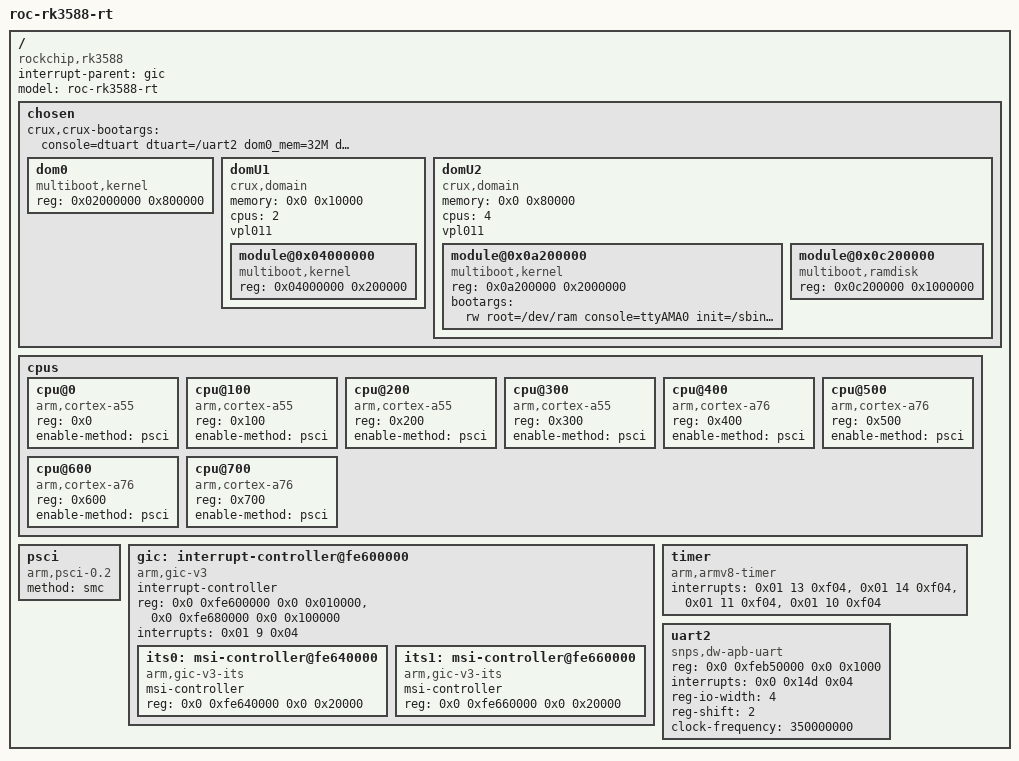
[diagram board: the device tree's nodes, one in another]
/******************************************************
 *                     _____     __  __
 *            /\/\/\/\/ __  \/\ / _\/__\
 *            \ - \ \ \ \/ // // _\/  \
 *             \/\/\_/\_/\/ \__\__\\/\/ @2025
 *
 *                  - Hustle Embedded -
 *****************************************************/

/dts-v1/;

/ {
	#address-cells = <2>;
	#size-cells = <2>;
	interrupt-parent = <&gic>;
	compatible = "rockchip,rk3588";
	model = "roc-rk3588-rt";

	/* ROC-RK3588-RT Android 12 u-boot: bdinfo
	 *
	 * arch_number = 0x00000000
	 * boot_params = 0x00000000
	 * DRAM bank   = 0x00000000
	 * -> start    = 0x00200000
	 * -> size     = 0x08200000
	 * DRAM bank   = 0x00000001
	 * -> start    = 0x09400000
	 * -> size     = 0xE6C00000
	 * baudrate    = 1500000 bps
	 * TLB addr    = 0xEFFF0000
	 * relocaddr   = 0xEDC35000
	 * reloc off   = 0xEDA35000
	 * irq_sp      = 0xEB9F9EA0
	 * sp start    = 0xEB9F9EA0
	 * Early malloc usage: 31f8 / 80000
	 * fdt_blob = 0000000008300000
	 */
	chosen {
		#address-cells = <1>;
		#size-cells = <1>;
		crux,crux-bootargs = "console=dtuart dtuart=/uart2 dom0_mem=32M dom0_max_vcpus=1 sched=rtds bootscrub=0 hmp-unsafe=true";

		dom0 {
			compatible = "multiboot,kernel","multiboot,module";
			reg = <0x02000000 0x800000>; // 8M
		};

		domU1 {
			compatible = "crux,domain";
			memory = <0x0 0x10000>; // 64M
			cpus = <2>;
			vpl011;

			module@0x04000000 {
				compatible = "multiboot,kernel","multiboot,module";
				reg = <0x04000000 0x200000>; // 2M
			};
		};

		domU2 {
			compatible = "crux,domain";
			memory = <0x0 0x80000>; // 512M
			cpus = <4>;
			vpl011;

			module@0x0a200000 {
				compatible = "multiboot,kernel","multiboot,module";
				reg = <0x0a200000 0x2000000>; // 32M
				bootargs = "rw root=/dev/ram console=ttyAMA0 init=/sbin/init";
			};

			module@0x0c200000 {
				compatible = "multiboot,ramdisk","multiboot,module";
				reg = <0x0c200000 0x1000000>; // 16M
			};
		};
	};

	cpus {
		#address-cells = <1>;
		#size-cells = <0>;

		cpu@0 {
			device_type = "cpu";
			compatible = "arm,cortex-a55";
			reg = <0x0>;
			enable-method = "psci";
		};

		cpu@100 {
			device_type = "cpu";
			compatible = "arm,cortex-a55";
			reg = <0x100>;
			enable-method = "psci";
		};

		cpu@200 {
			device_type = "cpu";
			compatible = "arm,cortex-a55";
			reg = <0x200>;
			enable-method = "psci";
		};

		cpu@300 {
			device_type = "cpu";
			compatible = "arm,cortex-a55";
			reg = <0x300>;
			enable-method = "psci";
		};

		cpu@400 {
			device_type = "cpu";
			compatible = "arm,cortex-a76";
			reg = <0x400>;
			enable-method = "psci";
		};

		cpu@500 {
			device_type = "cpu";
			compatible = "arm,cortex-a76";
			reg = <0x500>;
			enable-method = "psci";
		};

		cpu@600 {
			device_type = "cpu";
			compatible = "arm,cortex-a76";
			reg = <0x600>;
			enable-method = "psci";
		};

		cpu@700 {
			device_type = "cpu";
			compatible = "arm,cortex-a76";
			reg = <0x700>;
			enable-method = "psci";
		};
	};

	psci {
		compatible = "arm,psci-0.2";
		method = "smc";
	};

	gic: interrupt-controller@fe600000  {
		compatible = "arm,gic-v3";
		#interrupt-cells = <3>;
		#address-cells = <2>;
		#size-cells = <2>;
		interrupt-controller;
		ranges;

		reg = <0x0 0xfe600000 0x0 0x010000>, /* GICD */
		      <0x0 0xfe680000 0x0 0x100000>; /* GICR */
		interrupts = <0x01 9 0x04>;

		its0: msi-controller@fe640000 {
			compatible = "arm,gic-v3-its";
			msi-controller;
			#msi-cells = <1>;
			reg = <0x0 0xfe640000 0x0 0x20000>;
		};

		its1: msi-controller@fe660000 {
			compatible = "arm,gic-v3-its";
			msi-controller;
			#msi-cells = <1>;
			reg = <0x0 0xfe660000 0x0 0x20000>;
		};
	};

	timer {
		compatible = "arm,armv8-timer";
		interrupts =
			<0x01 13 0xf04>,
			<0x01 14 0xf04>,
			<0x01 11 0xf04>,
			<0x01 10 0xf04>;
	};

	uart2 {
		compatible = "snps,dw-apb-uart", "ns16550";
		reg = <0x0 0xfeb50000 0x0 0x1000>;
		interrupts = <0x0 0x14d 0x04>;
		reg-io-width = <4>;
		reg-shift = <2>;
		clock-frequency = <350000000>;
	};
};
